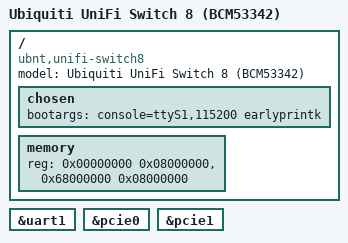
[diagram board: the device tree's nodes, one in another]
/*
 * DTS for Unifi Switch 8 port
 *
 * Copyright (C) 2017 Florian Fainelli <f.fainelli@gmail.com>
 *
 * Licensed under the GNU/GPL. See COPYING for details.
 */

/dts-v1/;

#include "bcm-hr2.dtsi"

/ {
	compatible = "ubnt,unifi-switch8", "brcm,bcm53342", "brcm,hr2";
	model = "Ubiquiti UniFi Switch 8 (BCM53342)";

	/* Hurricane 2 designs use the second UART */
	chosen {
		bootargs = "console=ttyS1,115200 earlyprintk";
	};

	memory {
		reg = <0x00000000 0x08000000>,
		      <0x68000000 0x08000000>;
	};
};

&uart1 {
	status = "okay";
};

&pcie0 {
	status = "okay";
};

&pcie1 {
	status = "okay";
};
